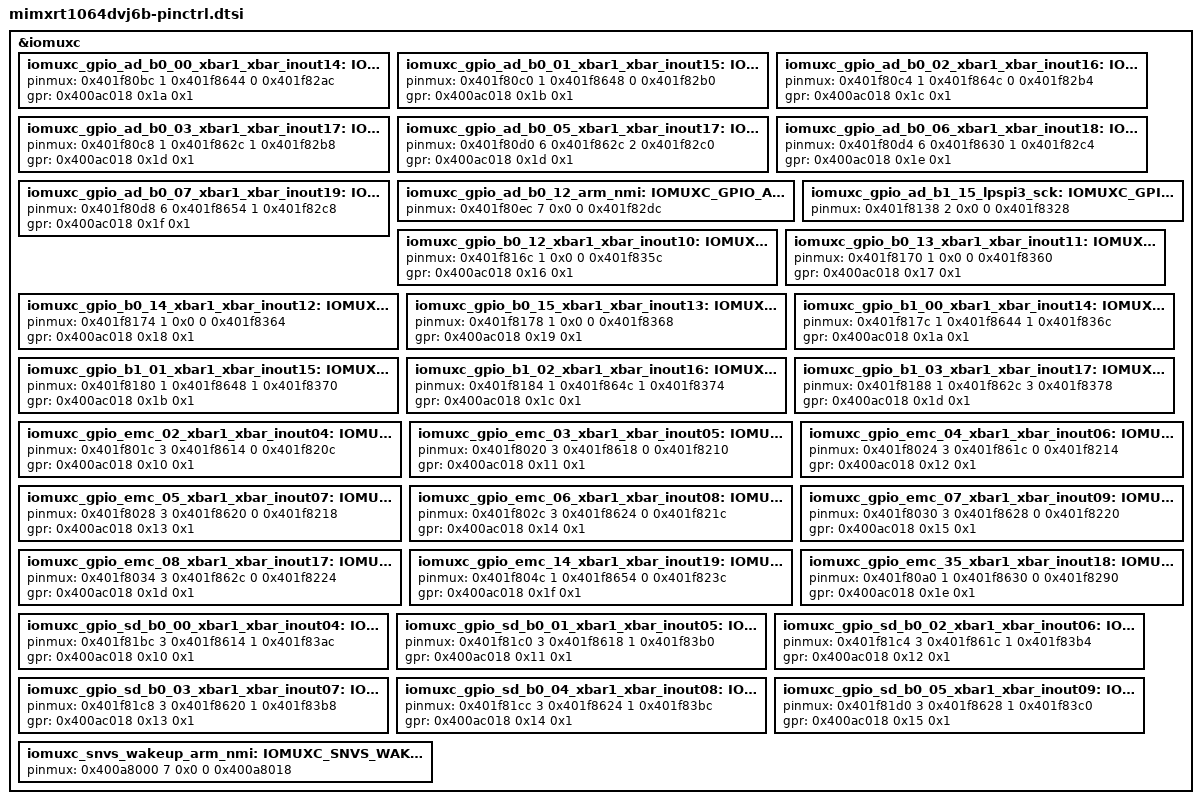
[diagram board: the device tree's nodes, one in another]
/*
 * Copyright 2024, NXP
 * SPDX-License-Identifier: Apache-2.0
 *
 * Note: File generated by gen_soc_headers.py
 * from configuration data for MIMXRT1064DVJ6B
 */

/*
 * Delta-deduplicated by dedup_pinctrl.py:
 * based on mimxrt1064dvj6a-pinctrl.dtsi with this part's differences applied
 * below (0 removed, 33 changed,
 * 0 added). Regenerate with dedup_pinctrl.py;
 * do not edit by hand.
 * target-hash: 304d2df1a5f7ddd6
 */

#include "mimxrt1064dvj6a-pinctrl.dtsi"

/delete-node/ &iomuxc_gpio_ad_b0_00_xbar1_xbar_inout14;
/delete-node/ &iomuxc_gpio_ad_b0_01_xbar1_xbar_inout15;
/delete-node/ &iomuxc_gpio_ad_b0_02_xbar1_xbar_inout16;
/delete-node/ &iomuxc_gpio_ad_b0_03_xbar1_xbar_inout17;
/delete-node/ &iomuxc_gpio_ad_b0_05_xbar1_xbar_inout17;
/delete-node/ &iomuxc_gpio_ad_b0_06_xbar1_xbar_inout18;
/delete-node/ &iomuxc_gpio_ad_b0_07_xbar1_xbar_inout19;
/delete-node/ &iomuxc_gpio_ad_b0_12_arm_nmi;
/delete-node/ &iomuxc_gpio_ad_b1_15_lpspi3_sck;
/delete-node/ &iomuxc_gpio_b0_12_xbar1_xbar_inout10;
/delete-node/ &iomuxc_gpio_b0_13_xbar1_xbar_inout11;
/delete-node/ &iomuxc_gpio_b0_14_xbar1_xbar_inout12;
/delete-node/ &iomuxc_gpio_b0_15_xbar1_xbar_inout13;
/delete-node/ &iomuxc_gpio_b1_00_xbar1_xbar_inout14;
/delete-node/ &iomuxc_gpio_b1_01_xbar1_xbar_inout15;
/delete-node/ &iomuxc_gpio_b1_02_xbar1_xbar_inout16;
/delete-node/ &iomuxc_gpio_b1_03_xbar1_xbar_inout17;
/delete-node/ &iomuxc_gpio_emc_02_xbar1_xbar_inout04;
/delete-node/ &iomuxc_gpio_emc_03_xbar1_xbar_inout05;
/delete-node/ &iomuxc_gpio_emc_04_xbar1_xbar_inout06;
/delete-node/ &iomuxc_gpio_emc_05_xbar1_xbar_inout07;
/delete-node/ &iomuxc_gpio_emc_06_xbar1_xbar_inout08;
/delete-node/ &iomuxc_gpio_emc_07_xbar1_xbar_inout09;
/delete-node/ &iomuxc_gpio_emc_08_xbar1_xbar_inout17;
/delete-node/ &iomuxc_gpio_emc_14_xbar1_xbar_inout19;
/delete-node/ &iomuxc_gpio_emc_35_xbar1_xbar_inout18;
/delete-node/ &iomuxc_gpio_sd_b0_00_xbar1_xbar_inout04;
/delete-node/ &iomuxc_gpio_sd_b0_01_xbar1_xbar_inout05;
/delete-node/ &iomuxc_gpio_sd_b0_02_xbar1_xbar_inout06;
/delete-node/ &iomuxc_gpio_sd_b0_03_xbar1_xbar_inout07;
/delete-node/ &iomuxc_gpio_sd_b0_04_xbar1_xbar_inout08;
/delete-node/ &iomuxc_gpio_sd_b0_05_xbar1_xbar_inout09;
/delete-node/ &iomuxc_snvs_wakeup_arm_nmi;

&iomuxc {
	/omit-if-no-ref/ iomuxc_gpio_ad_b0_00_xbar1_xbar_inout14: IOMUXC_GPIO_AD_B0_00_XBAR1_XBAR_INOUT14 {
		pinmux = <0x401f80bc 1 0x401f8644 0 0x401f82ac>;
		gpr = <0x400ac018 0x1a 0x1>;
	};
	/omit-if-no-ref/ iomuxc_gpio_ad_b0_01_xbar1_xbar_inout15: IOMUXC_GPIO_AD_B0_01_XBAR1_XBAR_INOUT15 {
		pinmux = <0x401f80c0 1 0x401f8648 0 0x401f82b0>;
		gpr = <0x400ac018 0x1b 0x1>;
	};
	/omit-if-no-ref/ iomuxc_gpio_ad_b0_02_xbar1_xbar_inout16: IOMUXC_GPIO_AD_B0_02_XBAR1_XBAR_INOUT16 {
		pinmux = <0x401f80c4 1 0x401f864c 0 0x401f82b4>;
		gpr = <0x400ac018 0x1c 0x1>;
	};
	/omit-if-no-ref/ iomuxc_gpio_ad_b0_03_xbar1_xbar_inout17: IOMUXC_GPIO_AD_B0_03_XBAR1_XBAR_INOUT17 {
		pinmux = <0x401f80c8 1 0x401f862c 1 0x401f82b8>;
		gpr = <0x400ac018 0x1d 0x1>;
	};
	/omit-if-no-ref/ iomuxc_gpio_ad_b0_05_xbar1_xbar_inout17: IOMUXC_GPIO_AD_B0_05_XBAR1_XBAR_INOUT17 {
		pinmux = <0x401f80d0 6 0x401f862c 2 0x401f82c0>;
		gpr = <0x400ac018 0x1d 0x1>;
	};
	/omit-if-no-ref/ iomuxc_gpio_ad_b0_06_xbar1_xbar_inout18: IOMUXC_GPIO_AD_B0_06_XBAR1_XBAR_INOUT18 {
		pinmux = <0x401f80d4 6 0x401f8630 1 0x401f82c4>;
		gpr = <0x400ac018 0x1e 0x1>;
	};
	/omit-if-no-ref/ iomuxc_gpio_ad_b0_07_xbar1_xbar_inout19: IOMUXC_GPIO_AD_B0_07_XBAR1_XBAR_INOUT19 {
		pinmux = <0x401f80d8 6 0x401f8654 1 0x401f82c8>;
		gpr = <0x400ac018 0x1f 0x1>;
	};
	/omit-if-no-ref/ iomuxc_gpio_ad_b0_12_arm_nmi: IOMUXC_GPIO_AD_B0_12_ARM_NMI {
		pinmux = <0x401f80ec 7 0x0 0 0x401f82dc>;
	};
	/omit-if-no-ref/ iomuxc_gpio_ad_b1_15_lpspi3_sck: IOMUXC_GPIO_AD_B1_15_LPSPI3_SCK {
		pinmux = <0x401f8138 2 0x0 0 0x401f8328>;
	};
	/omit-if-no-ref/ iomuxc_gpio_b0_12_xbar1_xbar_inout10: IOMUXC_GPIO_B0_12_XBAR1_XBAR_INOUT10 {
		pinmux = <0x401f816c 1 0x0 0 0x401f835c>;
		gpr = <0x400ac018 0x16 0x1>;
	};
	/omit-if-no-ref/ iomuxc_gpio_b0_13_xbar1_xbar_inout11: IOMUXC_GPIO_B0_13_XBAR1_XBAR_INOUT11 {
		pinmux = <0x401f8170 1 0x0 0 0x401f8360>;
		gpr = <0x400ac018 0x17 0x1>;
	};
	/omit-if-no-ref/ iomuxc_gpio_b0_14_xbar1_xbar_inout12: IOMUXC_GPIO_B0_14_XBAR1_XBAR_INOUT12 {
		pinmux = <0x401f8174 1 0x0 0 0x401f8364>;
		gpr = <0x400ac018 0x18 0x1>;
	};
	/omit-if-no-ref/ iomuxc_gpio_b0_15_xbar1_xbar_inout13: IOMUXC_GPIO_B0_15_XBAR1_XBAR_INOUT13 {
		pinmux = <0x401f8178 1 0x0 0 0x401f8368>;
		gpr = <0x400ac018 0x19 0x1>;
	};
	/omit-if-no-ref/ iomuxc_gpio_b1_00_xbar1_xbar_inout14: IOMUXC_GPIO_B1_00_XBAR1_XBAR_INOUT14 {
		pinmux = <0x401f817c 1 0x401f8644 1 0x401f836c>;
		gpr = <0x400ac018 0x1a 0x1>;
	};
	/omit-if-no-ref/ iomuxc_gpio_b1_01_xbar1_xbar_inout15: IOMUXC_GPIO_B1_01_XBAR1_XBAR_INOUT15 {
		pinmux = <0x401f8180 1 0x401f8648 1 0x401f8370>;
		gpr = <0x400ac018 0x1b 0x1>;
	};
	/omit-if-no-ref/ iomuxc_gpio_b1_02_xbar1_xbar_inout16: IOMUXC_GPIO_B1_02_XBAR1_XBAR_INOUT16 {
		pinmux = <0x401f8184 1 0x401f864c 1 0x401f8374>;
		gpr = <0x400ac018 0x1c 0x1>;
	};
	/omit-if-no-ref/ iomuxc_gpio_b1_03_xbar1_xbar_inout17: IOMUXC_GPIO_B1_03_XBAR1_XBAR_INOUT17 {
		pinmux = <0x401f8188 1 0x401f862c 3 0x401f8378>;
		gpr = <0x400ac018 0x1d 0x1>;
	};
	/omit-if-no-ref/ iomuxc_gpio_emc_02_xbar1_xbar_inout04: IOMUXC_GPIO_EMC_02_XBAR1_XBAR_INOUT04 {
		pinmux = <0x401f801c 3 0x401f8614 0 0x401f820c>;
		gpr = <0x400ac018 0x10 0x1>;
	};
	/omit-if-no-ref/ iomuxc_gpio_emc_03_xbar1_xbar_inout05: IOMUXC_GPIO_EMC_03_XBAR1_XBAR_INOUT05 {
		pinmux = <0x401f8020 3 0x401f8618 0 0x401f8210>;
		gpr = <0x400ac018 0x11 0x1>;
	};
	/omit-if-no-ref/ iomuxc_gpio_emc_04_xbar1_xbar_inout06: IOMUXC_GPIO_EMC_04_XBAR1_XBAR_INOUT06 {
		pinmux = <0x401f8024 3 0x401f861c 0 0x401f8214>;
		gpr = <0x400ac018 0x12 0x1>;
	};
	/omit-if-no-ref/ iomuxc_gpio_emc_05_xbar1_xbar_inout07: IOMUXC_GPIO_EMC_05_XBAR1_XBAR_INOUT07 {
		pinmux = <0x401f8028 3 0x401f8620 0 0x401f8218>;
		gpr = <0x400ac018 0x13 0x1>;
	};
	/omit-if-no-ref/ iomuxc_gpio_emc_06_xbar1_xbar_inout08: IOMUXC_GPIO_EMC_06_XBAR1_XBAR_INOUT08 {
		pinmux = <0x401f802c 3 0x401f8624 0 0x401f821c>;
		gpr = <0x400ac018 0x14 0x1>;
	};
	/omit-if-no-ref/ iomuxc_gpio_emc_07_xbar1_xbar_inout09: IOMUXC_GPIO_EMC_07_XBAR1_XBAR_INOUT09 {
		pinmux = <0x401f8030 3 0x401f8628 0 0x401f8220>;
		gpr = <0x400ac018 0x15 0x1>;
	};
	/omit-if-no-ref/ iomuxc_gpio_emc_08_xbar1_xbar_inout17: IOMUXC_GPIO_EMC_08_XBAR1_XBAR_INOUT17 {
		pinmux = <0x401f8034 3 0x401f862c 0 0x401f8224>;
		gpr = <0x400ac018 0x1d 0x1>;
	};
	/omit-if-no-ref/ iomuxc_gpio_emc_14_xbar1_xbar_inout19: IOMUXC_GPIO_EMC_14_XBAR1_XBAR_INOUT19 {
		pinmux = <0x401f804c 1 0x401f8654 0 0x401f823c>;
		gpr = <0x400ac018 0x1f 0x1>;
	};
	/omit-if-no-ref/ iomuxc_gpio_emc_35_xbar1_xbar_inout18: IOMUXC_GPIO_EMC_35_XBAR1_XBAR_INOUT18 {
		pinmux = <0x401f80a0 1 0x401f8630 0 0x401f8290>;
		gpr = <0x400ac018 0x1e 0x1>;
	};
	/omit-if-no-ref/ iomuxc_gpio_sd_b0_00_xbar1_xbar_inout04: IOMUXC_GPIO_SD_B0_00_XBAR1_XBAR_INOUT04 {
		pinmux = <0x401f81bc 3 0x401f8614 1 0x401f83ac>;
		gpr = <0x400ac018 0x10 0x1>;
	};
	/omit-if-no-ref/ iomuxc_gpio_sd_b0_01_xbar1_xbar_inout05: IOMUXC_GPIO_SD_B0_01_XBAR1_XBAR_INOUT05 {
		pinmux = <0x401f81c0 3 0x401f8618 1 0x401f83b0>;
		gpr = <0x400ac018 0x11 0x1>;
	};
	/omit-if-no-ref/ iomuxc_gpio_sd_b0_02_xbar1_xbar_inout06: IOMUXC_GPIO_SD_B0_02_XBAR1_XBAR_INOUT06 {
		pinmux = <0x401f81c4 3 0x401f861c 1 0x401f83b4>;
		gpr = <0x400ac018 0x12 0x1>;
	};
	/omit-if-no-ref/ iomuxc_gpio_sd_b0_03_xbar1_xbar_inout07: IOMUXC_GPIO_SD_B0_03_XBAR1_XBAR_INOUT07 {
		pinmux = <0x401f81c8 3 0x401f8620 1 0x401f83b8>;
		gpr = <0x400ac018 0x13 0x1>;
	};
	/omit-if-no-ref/ iomuxc_gpio_sd_b0_04_xbar1_xbar_inout08: IOMUXC_GPIO_SD_B0_04_XBAR1_XBAR_INOUT08 {
		pinmux = <0x401f81cc 3 0x401f8624 1 0x401f83bc>;
		gpr = <0x400ac018 0x14 0x1>;
	};
	/omit-if-no-ref/ iomuxc_gpio_sd_b0_05_xbar1_xbar_inout09: IOMUXC_GPIO_SD_B0_05_XBAR1_XBAR_INOUT09 {
		pinmux = <0x401f81d0 3 0x401f8628 1 0x401f83c0>;
		gpr = <0x400ac018 0x15 0x1>;
	};
	/omit-if-no-ref/ iomuxc_snvs_wakeup_arm_nmi: IOMUXC_SNVS_WAKEUP_ARM_NMI {
		pinmux = <0x400a8000 7 0x0 0 0x400a8018>;
	};
};
